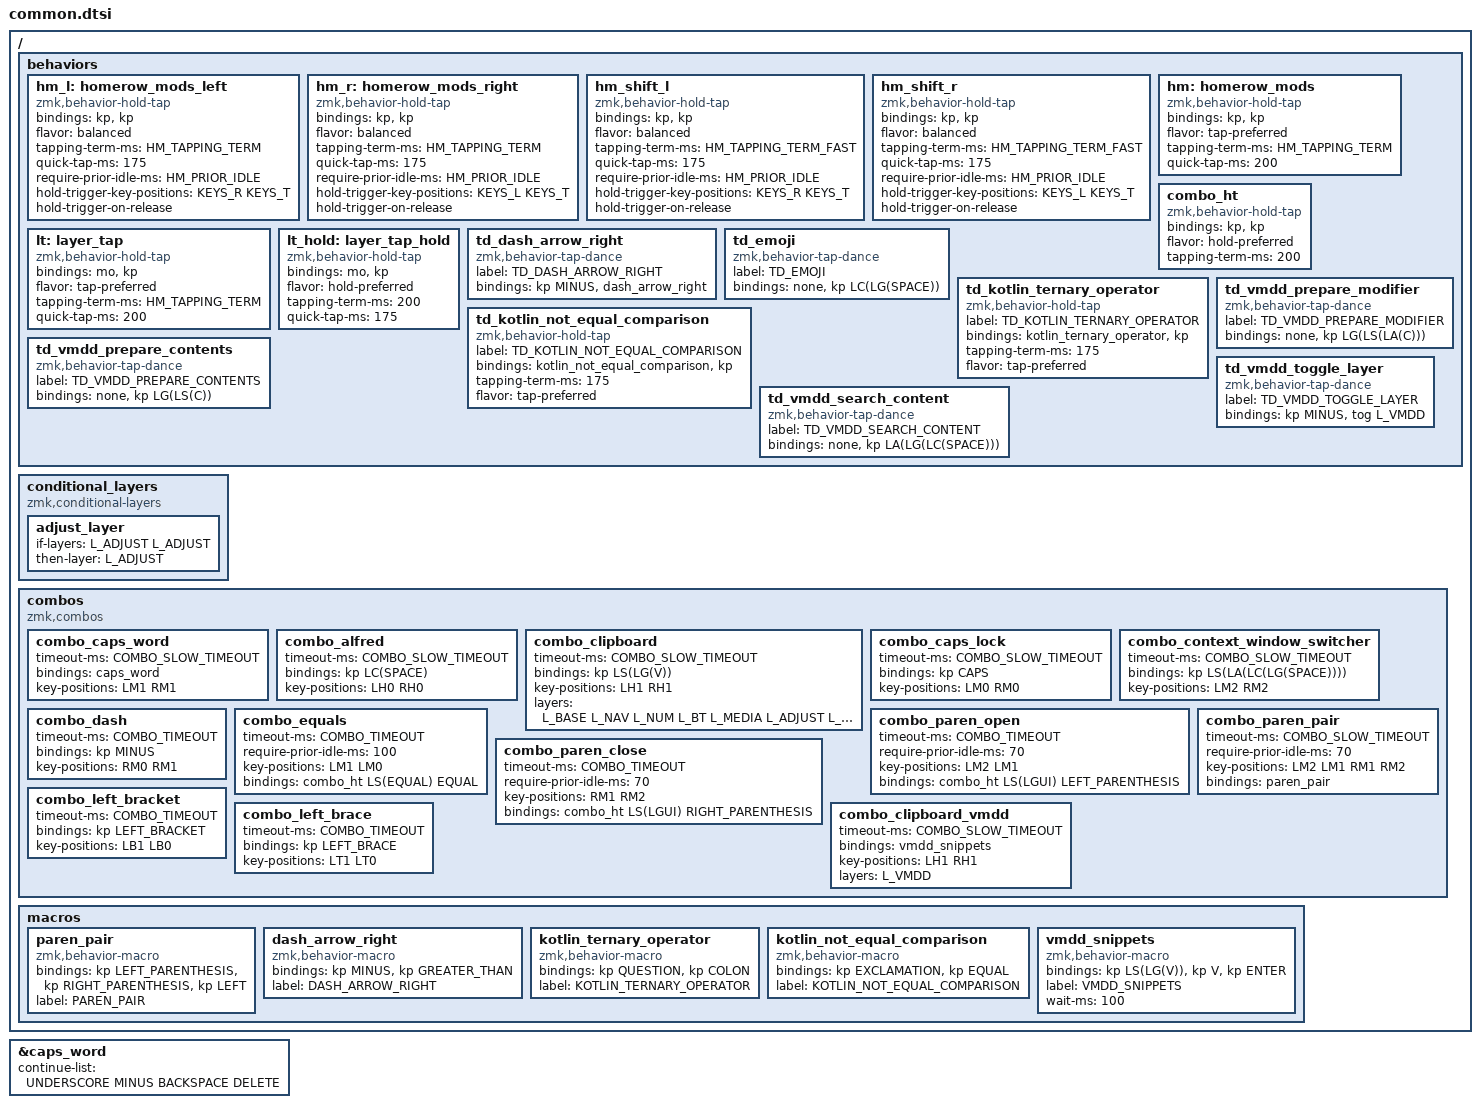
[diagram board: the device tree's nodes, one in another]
/*
 * Shared behaviors, combos and macros for the Cornix and Corne keymaps.
 *
 * Include AFTER the board's key-position header (includes/cornix54.h or
 * includes/corne42.h): key positions here use its names (LM1, RH0, ...).
 * Each board's .keymap defines only its own layer grids.
 */

#include "zmk-helpers/helper.h"

// tap windows for ctl alt and gui

#define HM_TAPPING_TERM 280
#define HM_TAPPING_REPEAT 200

// quick tapping for shift

#define HM_TAPPING_TERM_FAST 200
#define HM_PRIOR_IDLE 70
#define COMBO_TIMEOUT 18
#define COMBO_SLOW_TIMEOUT 30

// Layer indices: must match the order of layers in each board's keymap node.

#define L_BASE    0
#define L_NAV     1
#define L_NUM     2
#define L_BT      3
#define L_MEDIA   4
#define L_ADJUST  5  // placeholder
#define L_NAVI    6  // placeholder
#define L_NUMPAD  7  // placeholder
#define L_DEBUG   8  // placeholder
#define L_MOUSE   9
#define L_VMDD   10

// https://github.com/urob/zmk-config/tree/main#timeless-homerow-mods

#define KEYS_L LT0 LT1 LT2 LT3 LT4 LT5 LM0 LM1 LM2 LM3 LM4 LM5 LB0 LB1 LB2 LB3 LB4 LB5  // left hand
#define KEYS_R RT0 RT1 RT2 RT3 RT4 RT5 RM0 RM1 RM2 RM3 RM4 RM5 RB0 RB1 RB2 RB3 RB4 RB5  // right hand
#define THUMBS LH1 LH0 RH0 RH1
#define KEYS_T LH1 LH0 RH0 RH1
#define ZMK_POINTING_DEFAULT_SCRL_VAL 15

#include <behaviors.dtsi>
#include <dt-bindings/zmk/bt.h>
#include <dt-bindings/zmk/ext_power.h>
#include <dt-bindings/zmk/keys.h>
#include <dt-bindings/zmk/pointing.h>

&caps_word { continue-list = <UNDERSCORE MINUS BACKSPACE DELETE>; };

/ {
    // Activate ADJUST layer by pressing raise and lower

    behaviors {
        hm_l: homerow_mods_left {
            compatible = "zmk,behavior-hold-tap";
            #binding-cells = <2>;
            bindings = <&kp>, <&kp>;

            flavor = "balanced";
            tapping-term-ms = <HM_TAPPING_TERM>;
            quick-tap-ms = <175>;                // repeat on tap-into-hold
            require-prior-idle-ms = <HM_PRIOR_IDLE>;
            hold-trigger-key-positions = <KEYS_R KEYS_T>;
            hold-trigger-on-release;
        };

        hm_r: homerow_mods_right {
            compatible = "zmk,behavior-hold-tap";
            #binding-cells = <2>;
            bindings = <&kp>, <&kp>;

            flavor = "balanced";
            tapping-term-ms = <HM_TAPPING_TERM>;
            quick-tap-ms = <175>;
            require-prior-idle-ms = <HM_PRIOR_IDLE>;
            hold-trigger-key-positions = <KEYS_L KEYS_T>;
            hold-trigger-on-release;
        };

        // Positional Homerow mods for shift
        // Use faster tapping term and disable some features that may
        // cause false negatives.

        hm_shift_l: hm_shift_l {
            compatible = "zmk,behavior-hold-tap";
            #binding-cells = <2>;
            bindings = <&kp>, <&kp>;

            flavor = "balanced";
            tapping-term-ms = <HM_TAPPING_TERM_FAST>;
            quick-tap-ms = <175>;
            require-prior-idle-ms = <HM_PRIOR_IDLE>;
            hold-trigger-key-positions = <KEYS_R KEYS_T>;
            hold-trigger-on-release;
        };

        hm_shift_r: hm_shift_r {
            compatible = "zmk,behavior-hold-tap";
            #binding-cells = <2>;
            bindings = <&kp>, <&kp>;

            flavor = "balanced";
            tapping-term-ms = <HM_TAPPING_TERM_FAST>;
            quick-tap-ms = <175>;
            require-prior-idle-ms = <HM_PRIOR_IDLE>;
            hold-trigger-key-positions = <KEYS_L KEYS_T>;

            // for quick tapping; shift+~

            hold-trigger-on-release;
        };

        /*
         * Non-Positional Homerow Mods
         * Used for &mm_grescm_gui behavior on left hand.
         *
         * Usage: &hm LSHFT T
         * Tap: T
         * Tap-Tap-Hold: Repeat T
         * Hold: LSHIFT
         */

        hm: homerow_mods {
            compatible = "zmk,behavior-hold-tap";
            #binding-cells = <2>;
            bindings = <&kp>, <&kp>;

            flavor = "tap-preferred";
            tapping-term-ms = <HM_TAPPING_TERM>;
            quick-tap-ms = <200>;
        };

        /*
         * Used by the D+F / J+K paren combos below.
         * hold-preferred: fires the hold the instant another key is pressed
         * while still held, so Cmd+Shift engages immediately when you press
         * an arrow key to select — no need to wait out tapping-term-ms.
         */

        combo_ht: combo_ht {
            compatible = "zmk,behavior-hold-tap";
            #binding-cells = <2>;
            bindings = <&kp>, <&kp>;

            flavor = "hold-preferred";
            tapping-term-ms = <200>;
        };

        lt: layer_tap {
            compatible = "zmk,behavior-hold-tap";
            #binding-cells = <2>;
            bindings = <&mo>, <&kp>;

            // tap-preferred: protects taps (e.g. SPACE) from accidentally
            // engaging the layer during fast typing rolls.

            flavor = "tap-preferred";
            tapping-term-ms = <HM_TAPPING_TERM>;
            quick-tap-ms = <200>;
        };

        lt_hold: layer_tap_hold {
            compatible = "zmk,behavior-hold-tap";
            #binding-cells = <2>;
            bindings = <&mo>, <&kp>;

            // hold-preferred: the layer engages the instant the next key is
            // pressed, so symbols/numbers (e.g. "(") never fall through to the
            // base layer. Use for thumbs you hold-and-type-on.

            flavor = "hold-preferred";
            tapping-term-ms = <200>;
            quick-tap-ms = <175>;
        };

        td_dash_arrow_right: td_dash_arrow_right {
            compatible = "zmk,behavior-tap-dance";
            label = "TD_DASH_ARROW_RIGHT";
            #binding-cells = <0>;
            bindings = <&kp MINUS>, <&dash_arrow_right>;
        };

        td_emoji: td_emoji {
            compatible = "zmk,behavior-tap-dance";
            label = "TD_EMOJI";
            #binding-cells = <0>;
            bindings = <&none>, <&kp LC(LG(SPACE))>;
        };

        td_kotlin_ternary_operator: td_kotlin_ternary_operator {
            compatible = "zmk,behavior-hold-tap";
            label = "TD_KOTLIN_TERNARY_OPERATOR";
            bindings = <&kotlin_ternary_operator>, <&kp>;

            #binding-cells = <2>;
            tapping-term-ms = <175>;
            flavor = "tap-preferred";
        };

        td_kotlin_not_equal_comparison: td_kotlin_not_equal_comparison {
            compatible = "zmk,behavior-hold-tap";
            label = "TD_KOTLIN_NOT_EQUAL_COMPARISON";
            bindings = <&kotlin_not_equal_comparison>, <&kp>;

            #binding-cells = <2>;
            tapping-term-ms = <175>;
            flavor = "tap-preferred";
        };

        td_vmdd_prepare_contents: td_vmdd_prepare_contents {
            compatible = "zmk,behavior-tap-dance";
            label = "TD_VMDD_PREPARE_CONTENTS";
            #binding-cells = <0>;
            bindings = <&none>, <&kp LG(LS(C))>;
        };

        td_vmdd_prepare_modifier: td_vmdd_prepare_modifier {
            compatible = "zmk,behavior-tap-dance";
            label = "TD_VMDD_PREPARE_MODIFIER";
            #binding-cells = <0>;
            bindings = <&none>, <&kp LG(LS(LA(C)))>;
        };

        td_vmdd_search_content: td_vmdd_search_content {
            compatible = "zmk,behavior-tap-dance";
            label = "TD_VMDD_SEARCH_CONTENT";
            #binding-cells = <0>;
            bindings = <&none>, <&kp LA(LG(LC(SPACE)))>;
        };

        td_vmdd_toggle_layer: td_vmdd_toggle_layer {
            compatible = "zmk,behavior-tap-dance";
            label = "TD_VMDD_TOGGLE_LAYER";
            #binding-cells = <0>;
            bindings = <&kp MINUS>, <&tog L_VMDD>;
        };
    };

    conditional_layers {
        compatible = "zmk,conditional-layers";

        adjust_layer {
            if-layers = <L_ADJUST L_ADJUST>;
            then-layer = <L_ADJUST>;
        };
    };

    combos {
        compatible = "zmk,combos";

        combo_caps_word {
            timeout-ms = <COMBO_SLOW_TIMEOUT>;
            bindings = <&caps_word>;
            key-positions = <LM1 RM1>;
        };

        combo_alfred {
            timeout-ms = <COMBO_SLOW_TIMEOUT>;
            bindings = <&kp LC(SPACE)>;
            key-positions = <LH0 RH0>;
        };

        combo_clipboard {
            timeout-ms = <COMBO_SLOW_TIMEOUT>;
            bindings = <&kp LS(LG(V))>;
            key-positions = <LH1 RH1>;
            layers = <L_BASE L_NAV L_NUM L_BT L_MEDIA L_ADJUST L_NAVI L_NUMPAD L_DEBUG L_MOUSE>;
        };

        combo_caps_lock {
            timeout-ms = <COMBO_SLOW_TIMEOUT>;
            bindings = <&kp CAPS>;
            key-positions = <LM0 RM0>;
        };

        combo_context_window_switcher {
            timeout-ms = <COMBO_SLOW_TIMEOUT>;
            bindings = <&kp LS(LA(LC(LG(SPACE))))>;
            key-positions = <LM2 RM2>;
        };

        combo_dash {
            timeout-ms = <COMBO_TIMEOUT>;
            bindings = <&kp MINUS>;
            key-positions = <RM0 RM1>;
        };

        combo_equals {
            timeout-ms = <COMBO_TIMEOUT>;
            require-prior-idle-ms = <100>;
            key-positions = <LM1 LM0>;
            bindings = <&combo_ht LS(EQUAL) EQUAL>;
        };

        combo_paren_open {
            timeout-ms = <COMBO_TIMEOUT>;
            require-prior-idle-ms = <70>;
            key-positions = <LM2 LM1>;
            bindings = <&combo_ht LS(LGUI) LEFT_PARENTHESIS>;
        };

        combo_paren_close {
            timeout-ms = <COMBO_TIMEOUT>;
            require-prior-idle-ms = <70>;
            key-positions = <RM1 RM2>;
            bindings = <&combo_ht LS(LGUI) RIGHT_PARENTHESIS>;
        };

        combo_paren_pair {
            timeout-ms = <COMBO_SLOW_TIMEOUT>;
            require-prior-idle-ms = <70>;
            key-positions = <LM2 LM1 RM1 RM2>;
            bindings = <&paren_pair>;
        };

        combo_left_bracket {
            timeout-ms = <COMBO_TIMEOUT>;
            bindings = <&kp LEFT_BRACKET>;
            key-positions = <LB1 LB0>;
        };

        combo_left_brace {
            timeout-ms = <COMBO_TIMEOUT>;
            bindings = <&kp LEFT_BRACE>;
            key-positions = <LT1 LT0>;
        };

        combo_clipboard_vmdd {
            timeout-ms = <COMBO_SLOW_TIMEOUT>;
            bindings = <&vmdd_snippets>;
            key-positions = <LH1 RH1>;
            layers = <L_VMDD>;
        };
    };

    macros {
        paren_pair: paren_pair {
            compatible = "zmk,behavior-macro";
            #binding-cells = <0>;
            bindings = <&kp LEFT_PARENTHESIS &kp RIGHT_PARENTHESIS &kp LEFT>;
            label = "PAREN_PAIR";
        };

        dash_arrow_right: dash_arrow_right {
            compatible = "zmk,behavior-macro";
            #binding-cells = <0>;
            bindings = <&kp MINUS &kp GREATER_THAN>;
            label = "DASH_ARROW_RIGHT";
        };

        kotlin_ternary_operator: kotlin_ternary_operator {
            compatible = "zmk,behavior-macro";
            #binding-cells = <0>;
            bindings = <&kp QUESTION &kp COLON>;
            label = "KOTLIN_TERNARY_OPERATOR";
        };

        kotlin_not_equal_comparison: kotlin_not_equal_comparison {
            compatible = "zmk,behavior-macro";
            #binding-cells = <0>;
            bindings = <&kp EXCLAMATION &kp EQUAL>;
            label = "KOTLIN_NOT_EQUAL_COMPARISON";
        };

        vmdd_snippets: vmdd_snippets {
            compatible = "zmk,behavior-macro";
            #binding-cells = <0>;
            bindings = <&kp LS(LG(V)) &kp V &kp ENTER>;
            label = "VMDD_SNIPPETS";
            wait-ms = <100>;
        };
    };
};
